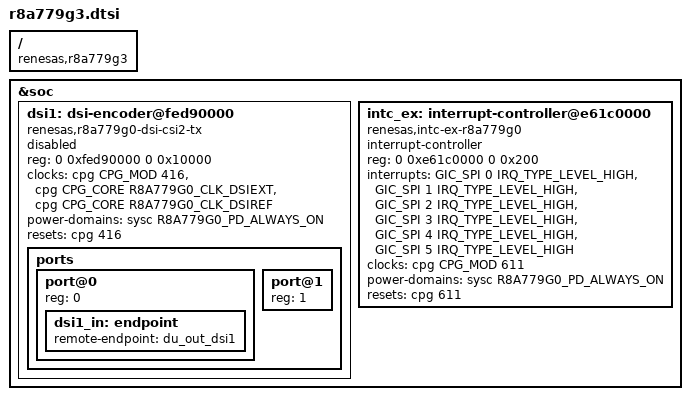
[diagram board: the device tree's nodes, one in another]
// SPDX-License-Identifier: (GPL-2.0-only OR BSD-2-Clause)
/*
 * Device Tree Source for the R-Car V4H (R8A779G3) SoC
 *
 * Copyright (C) 2024 Glider bv
 */

#include "r8a779g0.dtsi"

/ {
	compatible = "renesas,r8a779g3", "renesas,r8a779g0";

};

	&soc {
		dsi1: dsi-encoder@fed90000 {
			compatible = "renesas,r8a779g0-dsi-csi2-tx";
			reg = <0 0xfed90000 0 0x10000>;
			clocks = <&cpg CPG_MOD 416>,
				 <&cpg CPG_CORE R8A779G0_CLK_DSIEXT>,
				 <&cpg CPG_CORE R8A779G0_CLK_DSIREF>;
			clock-names = "fck", "dsi", "pll";
			power-domains = <&sysc R8A779G0_PD_ALWAYS_ON>;
			resets = <&cpg 416>;

			status = "disabled";

			ports {
				#address-cells = <1>;
				#size-cells = <0>;

				port@0 {
					reg = <0>;
					dsi1_in: endpoint {
						remote-endpoint = <&du_out_dsi1>;
					};
				};

				port@1 {
					reg = <1>;
				};
			};
		};

		intc_ex: interrupt-controller@e61c0000 {
			compatible = "renesas,intc-ex-r8a779g0", "renesas,irqc";
			#interrupt-cells = <2>;
			interrupt-controller;
			reg = <0 0xe61c0000 0 0x200>;
			interrupts = <GIC_SPI 0 IRQ_TYPE_LEVEL_HIGH>,
				     <GIC_SPI 1 IRQ_TYPE_LEVEL_HIGH>,
				     <GIC_SPI 2 IRQ_TYPE_LEVEL_HIGH>,
				     <GIC_SPI 3 IRQ_TYPE_LEVEL_HIGH>,
				     <GIC_SPI 4 IRQ_TYPE_LEVEL_HIGH>,
				     <GIC_SPI 5 IRQ_TYPE_LEVEL_HIGH>;
			clocks = <&cpg CPG_MOD 611>;
			power-domains = <&sysc R8A779G0_PD_ALWAYS_ON>;
			resets = <&cpg 611>;
		};
	};

